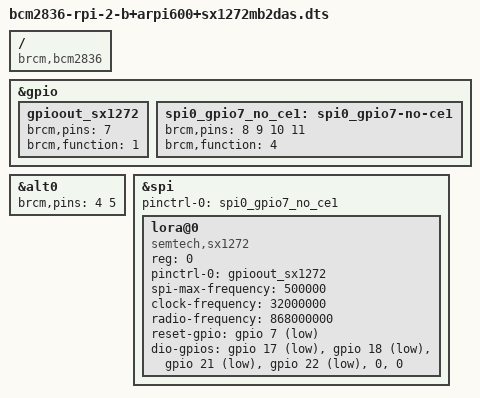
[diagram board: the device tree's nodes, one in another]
/*
 * Copyright (c) 2017 Andreas Färber
 *
 * SPDX-License-Identifier: GPL-2.0+ OR MIT
 */

/dts-v1/;
/plugin/;

/ {
	compatible = "brcm,bcm2836";

	#address-cells = <1>;
	#size-cells = <0>;

	fragment@0 {
		reg = <0>;

		target = <&gpio>;

		__overlay__ {
			gpioout_sx1272: gpioout_sx1272 {
				brcm,pins = <7>;
				brcm,function = <1>; /* gpio out */
			};

			spi0_gpio7_no_ce1: spi0_gpio7-no-ce1 {
				brcm,pins = <8 9 10 11>;
				brcm,function = <4>; /* alt0 */
			};
		};
	};

	fragment@1 {
		reg = <1>;

		target = <&alt0>;

		__overlay__ {
			/* Drop GPIO 7, SPI 8-11 */
			brcm,pins = <4 5>;
		};
	};

	fragment@2 {
		reg = <2>;

		target = <&spi>;

		__overlay__ {
			status = "okay";
			pinctrl-names = "default";
			pinctrl-0 = <&spi0_gpio7_no_ce1>;

			#address-cells = <1>;
			#size-cells = <0>;

			lora@0 {
				compatible = "semtech,sx1272";
				reg = <0>;
				pinctrl-names = "default";
				pinctrl-0 = <&gpioout_sx1272>;
				spi-max-frequency = <500000>;
				clock-frequency = <32000000>;
				radio-frequency = <868000000>;
				/*
				 * RESET == A0 ==  7
				 * DIO0  == P0 == 17
				 * DIO1  == P1 == 18
				 * DIO2  == P2 == 21/27
				 * DIO3  == P3 == 22
				 * DIO4
				 * DIO5
				 */
				reset-gpio = <&gpio 7 1>;
				dio-gpios = <&gpio 17 1>,
				            <&gpio 18 1>,
				            <&gpio 21 1>,
				            <&gpio 22 1>,
				            <0>,
				            <0>;
			};
		};
	};
};
